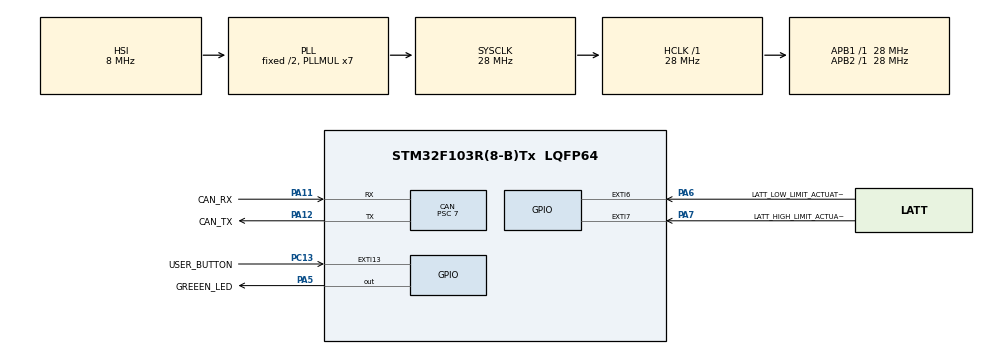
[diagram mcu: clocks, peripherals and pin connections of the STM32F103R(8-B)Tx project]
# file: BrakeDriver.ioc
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CAN.ABOM=ENABLE
CAN.BS1=CAN_BS1_2TQ
CAN.CalculateTimeBit=1000
CAN.CalculateTimeQuantum=250.0
CAN.Mode=CAN_MODE_NORMAL
CAN.NART=ENABLE
CAN.Prescaler=7
CAN.SJW=CAN_SJW_2TQ
Mcu.Family=STM32F1
Mcu.Name=STM32F103R(8-B)Tx
Mcu.Package=LQFP64
NVIC.CAN1_RX1_IRQn=true\:0\:0\:false\:true\:true\:4\:true\:true
NVIC.EXTI15_10_IRQn=true\:0\:0\:false\:false\:true\:true\:true
NVIC.PriorityGroup=NVIC_PRIORITYGROUP_2
NVIC.USB_HP_CAN1_TX_IRQn=true\:0\:0\:false\:true\:true\:3\:true\:true
PA11.GPIO_Label=CAN_RX
PA11.GPIO_PuPd=GPIO_PULLUP
PA11.Mode=Master
PA11.Signal=CAN_RX
PA12.GPIO_Label=CAN_TX
PA12.Mode=Master
PA12.Signal=CAN_TX
PA13.Mode=Serial_Wire
PA13.Signal=SYS_JTMS-SWDIO
PA14.Mode=Serial_Wire
PA14.Signal=SYS_JTCK-SWCLK
PA5.GPIO_Label=GREEEN_LED
PA5.Signal=GPIO_Output
PA6.GPIO_Label=LATT_LOW_LIMIT_ACTUATOR
PA6.GPIO_ModeDefaultEXTI=GPIO_MODE_IT_FALLING
PA6.GPIO_PuPd=GPIO_PULLDOWN
PA6.Signal=GPXTI6
PA7.GPIO_Label=LATT_HIGH_LIMIT_ACTUATOR
PA7.GPIO_PuPd=GPIO_PULLDOWN
PA7.Signal=GPXTI7
PC13-TAMPER-RTC.GPIO_Label=USER_BUTTON
PC13-TAMPER-RTC.Signal=GPXTI13
PD0-OSC_IN.Mode=HSE-External-Oscillator
PD0-OSC_IN.Signal=RCC_OSC_IN
PD1-OSC_OUT.Mode=HSE-External-Oscillator
PD1-OSC_OUT.Signal=RCC_OSC_OUT
ProjectManager.HeapSize=0x200
ProjectManager.StackSize=0x400
ProjectManager.TargetToolchain=TrueSTUDIO
RCC.AHBFreq_Value=28000000
RCC.APB1Freq_Value=28000000
RCC.APB1TimFreq_Value=28000000
RCC.APB2Freq_Value=28000000
RCC.APB2TimFreq_Value=28000000
RCC.HCLKFreq_Value=28000000
RCC.PLLMUL=RCC_PLL_MUL7
RCC.SYSCLKFreq_VALUE=28000000
RCC.SYSCLKSource=RCC_SYSCLKSOURCE_PLLCLK
RCC.USBFreq_Value=28000000
board=custom

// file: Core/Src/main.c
/* USER CODE BEGIN Header */
/**
  ******************************************************************************
  * @file           : main.c
  * @brief          : Main program body
  ******************************************************************************
  * @attention
  *
  * <h2><center>&copy; Copyright (c) 2019 STMicroelectronics.
  * All rights reserved.</center></h2>
  *
  * This software component is licensed by ST under BSD 3-Clause license,
  * the "License"; You may not use this file except in compliance with the
  * License. You may obtain a copy of the License at:
  *                        opensource.org/licenses/BSD-3-Clause
  *
  ******************************************************************************
  */
/* USER CODE END Header */

#include "main.h"
#include "can.h"
#include "gpio.h"

/* USER CODE BEGIN PM */
extern  CAN_HandleTypeDef hcan;
/* USER CODE END PM */

void SystemClock_Config(void);
static void MX_NVIC_Init(void);

/* USER CODE BEGIN 0 */
void hal_init(void){
	HAL_Init();

	SystemClock_Config();

	//todo Lukas  add "start" functions if needed
	MX_GPIO_Init();
	MX_CAN_Init();
	MX_NVIC_Init();

	// todo Lukas:  call HAL_Start... functions
	HAL_CAN_Start(&hcan);

	if (HAL_CAN_ActivateNotification(&hcan, CAN_IT_RX_FIFO0_MSG_PENDING) != HAL_OK)
	{
	    /* Notification Error */
	   Error_Handler();
	}

}
/* USER CODE END 0 */

void SystemClock_Config(void)
{
  RCC_OscInitTypeDef RCC_OscInitStruct = {0};
  RCC_ClkInitTypeDef RCC_ClkInitStruct = {0};

  /** Initializes the CPU, AHB and APB busses clocks
  */
  RCC_OscInitStruct.OscillatorType = RCC_OSCILLATORTYPE_HSI;
  RCC_OscInitStruct.HSIState = RCC_HSI_ON;
  RCC_OscInitStruct.HSICalibrationValue = RCC_HSICALIBRATION_DEFAULT;
  RCC_OscInitStruct.PLL.PLLState = RCC_PLL_ON;
  RCC_OscInitStruct.PLL.PLLSource = RCC_PLLSOURCE_HSI_DIV2;
  RCC_OscInitStruct.PLL.PLLMUL = RCC_PLL_MUL7;
  if (HAL_RCC_OscConfig(&RCC_OscInitStruct) != HAL_OK)
  {
    Error_Handler();
  }
  /** Initializes the CPU, AHB and APB busses clocks
  */
  RCC_ClkInitStruct.ClockType = RCC_CLOCKTYPE_HCLK|RCC_CLOCKTYPE_SYSCLK
                              |RCC_CLOCKTYPE_PCLK1|RCC_CLOCKTYPE_PCLK2;
  RCC_ClkInitStruct.SYSCLKSource = RCC_SYSCLKSOURCE_PLLCLK;
  RCC_ClkInitStruct.AHBCLKDivider = RCC_SYSCLK_DIV1;
  RCC_ClkInitStruct.APB1CLKDivider = RCC_HCLK_DIV1;
  RCC_ClkInitStruct.APB2CLKDivider = RCC_HCLK_DIV1;

  if (HAL_RCC_ClockConfig(&RCC_ClkInitStruct, FLASH_LATENCY_1) != HAL_OK)
  {
    Error_Handler();
  }
}

/**
  * @brief NVIC Configuration.
  * @retval None
  */
static void MX_NVIC_Init(void)
{
  /* USB_HP_CAN1_TX_IRQn interrupt configuration */
  HAL_NVIC_SetPriority(USB_HP_CAN1_TX_IRQn, 0, 0);
  HAL_NVIC_EnableIRQ(USB_HP_CAN1_TX_IRQn);
  /* CAN1_RX1_IRQn interrupt configuration */
  HAL_NVIC_SetPriority(CAN1_RX1_IRQn, 0, 0);
  HAL_NVIC_EnableIRQ(CAN1_RX1_IRQn);
}

void Error_Handler(void)
{
}

/************************ (C) COPYRIGHT STMicroelectronics *****END OF FILE****/
